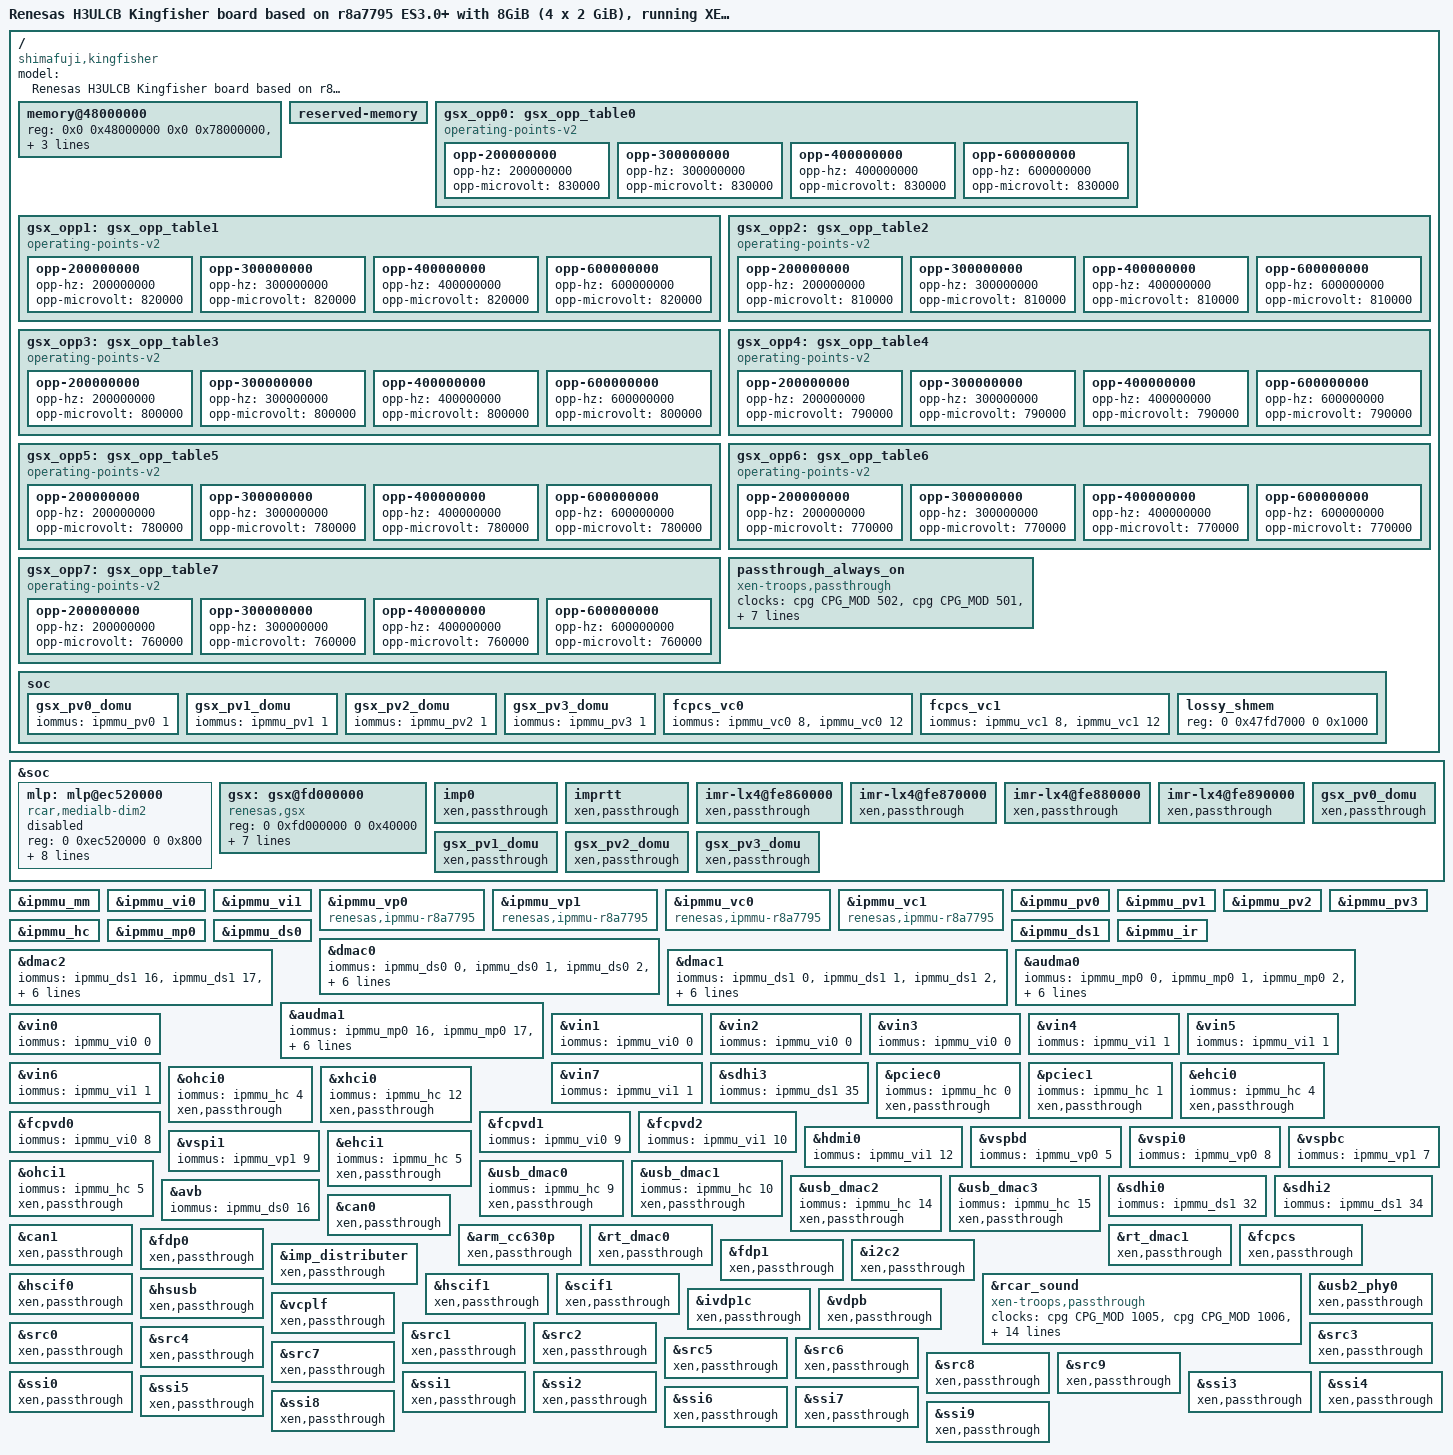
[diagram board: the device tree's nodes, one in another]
/*
 * Device Tree Source for the H3ULCB Kingfisher board
 * running XEN hypervisor
 *
 * Copyright (C) 2016-2018 Renesas Electronics Corp.
 * Copyright (C) 2016 Cogent Embedded, Inc.
 *
 * This file is licensed under the terms of the GNU General Public License
 * version 2.  This program is licensed "as is" without any warranty of any
 * kind, whether express or implied.
 */

#include "r8a77951-ulcb-kf.dts"
#include "xen-chosen.dtsi"

/ {
	model = "Renesas H3ULCB Kingfisher board based on r8a7795 ES3.0+ with 8GiB (4 x 2 GiB), running XEN hypervisor";
	compatible = "shimafuji,kingfisher", "renesas,h3ulcb",
			 "renesas,r8a7795";

	memory@48000000 {
		device_type = "memory";
		/* first 128MB is reserved for secure area. */
		reg = <0x0 0x48000000 0x0 0x78000000>,
			  <0x5 0x00000000 0x0 0x80000000>,
			  <0x6 0x00000000 0x0 0x80000000>,
			  <0x7 0x00000000 0x0 0x80000000>;
	};

	/delete-node/memory@500000000;
	/delete-node/memory@600000000;
	/delete-node/memory@700000000;

	reserved-memory {
		/delete-node/linux,cma@57000000;
		/delete-node/linux,multimedia@70000000;
	};

	/delete-node/mmngr;
	/delete-node/mmngrbuf;

	/*
	 * When creating DT for the guest domain Xen inserts only dummy CPU nodes.
	 * And the number of these inserted CPU nodes is equal to the number of
	 * vCPUs assigned to this domain. All CPU properties which original DT has,
	 * such as OPP, clock, regulator, etc are not passed to the guest’s DT.
	 *
	 * Example of guest vCPU node:
	 *
	 * cpu@0 {
	 *	   device_type = "cpu";
	 *	   compatible = "arm,armv8";
	 *	   enable-method = "psci";
	 *	   reg = <0x0>;
	 * };
	 *
	 * This results in the fact that all features expecting a57_x or a53_x
	 * CPU nodes to be present get broken. This is why we have to explicitly
	 * remove the following.
	 */
	/delete-node/thermal-zones;
	/delete-node/pmu_a57;
	/delete-node/pmu_a53;

	gsx_opp0: gsx_opp_table0 {
		compatible = "operating-points-v2";

		opp-200000000 {
			opp-hz = /bits/ 64 <200000000>;
			opp-microvolt = <830000>;
		};
		opp-300000000 {
			opp-hz = /bits/ 64 <300000000>;
			opp-microvolt = <830000>;
		};
		opp-400000000 {
			opp-hz = /bits/ 64 <400000000>;
			opp-microvolt = <830000>;
		};
		opp-600000000 {
			opp-hz = /bits/ 64 <600000000>;
			opp-microvolt = <830000>;
		};
	};

	gsx_opp1: gsx_opp_table1 {
		compatible = "operating-points-v2";

		opp-200000000 {
			opp-hz = /bits/ 64 <200000000>;
			opp-microvolt = <820000>;
		};
		opp-300000000 {
			opp-hz = /bits/ 64 <300000000>;
			opp-microvolt = <820000>;
		};
		opp-400000000 {
			opp-hz = /bits/ 64 <400000000>;
			opp-microvolt = <820000>;
		};
		opp-600000000 {
			opp-hz = /bits/ 64 <600000000>;
			opp-microvolt = <820000>;
		};
	};

	gsx_opp2: gsx_opp_table2 {
		compatible = "operating-points-v2";

		opp-200000000 {
			opp-hz = /bits/ 64 <200000000>;
			opp-microvolt = <810000>;
		};
		opp-300000000 {
			opp-hz = /bits/ 64 <300000000>;
			opp-microvolt = <810000>;
		};
		opp-400000000 {
			opp-hz = /bits/ 64 <400000000>;
			opp-microvolt = <810000>;
		};
		opp-600000000 {
			opp-hz = /bits/ 64 <600000000>;
			opp-microvolt = <810000>;
		};
	};

	gsx_opp3: gsx_opp_table3 {
		compatible = "operating-points-v2";

		opp-200000000 {
			opp-hz = /bits/ 64 <200000000>;
			opp-microvolt = <800000>;
		};
		opp-300000000 {
			opp-hz = /bits/ 64 <300000000>;
			opp-microvolt = <800000>;
		};
		opp-400000000 {
			opp-hz = /bits/ 64 <400000000>;
			opp-microvolt = <800000>;
		};
		opp-600000000 {
			opp-hz = /bits/ 64 <600000000>;
			opp-microvolt = <800000>;
		};
	};

	gsx_opp4: gsx_opp_table4 {
		compatible = "operating-points-v2";

		opp-200000000 {
			opp-hz = /bits/ 64 <200000000>;
			opp-microvolt = <790000>;
		};
		opp-300000000 {
			opp-hz = /bits/ 64 <300000000>;
			opp-microvolt = <790000>;
		};
		opp-400000000 {
			opp-hz = /bits/ 64 <400000000>;
			opp-microvolt = <790000>;
		};
		opp-600000000 {
			opp-hz = /bits/ 64 <600000000>;
			opp-microvolt = <790000>;
		};
	};

	gsx_opp5: gsx_opp_table5 {
		compatible = "operating-points-v2";

		opp-200000000 {
			opp-hz = /bits/ 64 <200000000>;
			opp-microvolt = <780000>;
		};
		opp-300000000 {
			opp-hz = /bits/ 64 <300000000>;
			opp-microvolt = <780000>;
		};
		opp-400000000 {
			opp-hz = /bits/ 64 <400000000>;
			opp-microvolt = <780000>;
		};
		opp-600000000 {
			opp-hz = /bits/ 64 <600000000>;
			opp-microvolt = <780000>;
		};
	};

	gsx_opp6: gsx_opp_table6 {
		compatible = "operating-points-v2";

		opp-200000000 {
			opp-hz = /bits/ 64 <200000000>;
			opp-microvolt = <770000>;
		};
		opp-300000000 {
			opp-hz = /bits/ 64 <300000000>;
			opp-microvolt = <770000>;
		};
		opp-400000000 {
			opp-hz = /bits/ 64 <400000000>;
			opp-microvolt = <770000>;
		};
		opp-600000000 {
			opp-hz = /bits/ 64 <600000000>;
			opp-microvolt = <770000>;
		};
	};

	gsx_opp7: gsx_opp_table7 {
		compatible = "operating-points-v2";

		opp-200000000 {
			opp-hz = /bits/ 64 <200000000>;
			opp-microvolt = <760000>;
		};
		opp-300000000 {
			opp-hz = /bits/ 64 <300000000>;
			opp-microvolt = <760000>;
		};
		opp-400000000 {
			opp-hz = /bits/ 64 <400000000>;
			opp-microvolt = <760000>;
		};
		opp-600000000 {
			opp-hz = /bits/ 64 <600000000>;
			opp-microvolt = <760000>;
		};
	};

	passthrough_always_on {
		compatible = "xen-troops,passthrough";
		clocks = <&cpg CPG_MOD 502>, /* audma0 */
				 <&cpg CPG_MOD 501>, /* audma1 */
				 <&cpg CPG_MOD 929>, /* audma1 */
				 <&cpg CPG_MOD 703>, <&cpg CPG_MOD 704>, /* hsusb */
				 <&cpg CPG_MOD 330>, /* usb_dmac0 */
				 <&cpg CPG_MOD 331>, /* usb_dmac1 */
				 <&cpg CPG_MOD 328>, /* xhci0 */
				 <&cpg CPG_MOD 702>, /* ohci1 */ /* ehci1 */
				 <&cpg CPG_MOD 218>,  /* dma-controller@e7300000 */
				 <&cpg CPG_MOD 217>,  /* dma-controller@e7310000 */
				 <&cpg CPG_MOD 219>, /* dma-controller@e6700000 */
				 <&cpg CPG_MOD 21>,  /* dma-controller@ffc10000 */
				 <&cpg CPG_MOD 16>,  /* dma-controller@ffc20000 */
				 <&cpg CPG_MOD 326>,  /* dma-controller@e6460000 */
				 <&cpg CPG_MOD 329>;  /* dma-controller@e6470000 */
	};

	/delete-node/sound@0;
};

/* ============================ Nodes, needed for config ===================== */
&soc {
	mlp: mlp@ec520000 {
		compatible = "rcar,medialb-dim2";
		reg = <0 0xec520000 0 0x800>;
		interrupts = <GIC_SPI 384 IRQ_TYPE_LEVEL_HIGH>,
			<GIC_SPI 385 IRQ_TYPE_LEVEL_HIGH>,
			<GIC_SPI 386 IRQ_TYPE_LEVEL_HIGH>,
			<GIC_SPI 387 IRQ_TYPE_LEVEL_HIGH>,
			<GIC_SPI 388 IRQ_TYPE_LEVEL_HIGH>;
		clocks = <&cpg CPG_MOD 802>;
		power-domains = <&sysc R8A7795_PD_ALWAYS_ON>;
		status = "disabled";
	};
	gsx: gsx@fd000000 {
		compatible = "renesas,gsx";
		reg = <0 0xfd000000 0 0x40000>;
		interrupts = <GIC_SPI 119 IRQ_TYPE_LEVEL_HIGH>;
		clocks = <&cpg CPG_MOD 112>;
		operating-points-v2 = <&gsx_opp0>, <&gsx_opp1>,
					  <&gsx_opp2>, <&gsx_opp3>,
					  <&gsx_opp4>, <&gsx_opp5>,
					  <&gsx_opp6>, <&gsx_opp7>;
		power-domains = <&sysc R8A7795_PD_3DG_E>;
		resets = <&cpg 112>;
	};
};

/* ============================ Enabled IPMMUs ===============================*/
&ipmmu_mm {
	status = "okay";
};

&ipmmu_vi0 {
	status = "okay";
};

&ipmmu_vi1 {
	status = "okay";
};

&ipmmu_vp0 {
	compatible = "renesas,ipmmu-r8a7795";
	status = "okay";
};

&ipmmu_vp1 {
	compatible = "renesas,ipmmu-r8a7795";
	status = "okay";
};

&ipmmu_vc0 {
	compatible = "renesas,ipmmu-r8a7795";
	status = "okay";
};

&ipmmu_vc1 {
	compatible = "renesas,ipmmu-r8a7795";
	status = "okay";
};

&ipmmu_pv0 {
	status = "okay";
};

&ipmmu_pv1 {
	status = "okay";
};

&ipmmu_pv2 {
	status = "okay";
};

&ipmmu_pv3 {
	status = "okay";
};

&ipmmu_hc {
	status = "okay";
};

&ipmmu_mp0 {
	status = "okay";
};

&ipmmu_ds0 {
	status = "okay";
};

&ipmmu_ds1 {
	status = "okay";
};

&ipmmu_ir {
	status = "okay";
};

/*=========================== Bus masters linked to IPMMUS ===================*/

&dmac0 {
	iommus = <&ipmmu_ds0 0>, <&ipmmu_ds0 1>,
			 <&ipmmu_ds0 2>, <&ipmmu_ds0 3>,
			 <&ipmmu_ds0 4>, <&ipmmu_ds0 5>,
			 <&ipmmu_ds0 6>, <&ipmmu_ds0 7>,
			 <&ipmmu_ds0 8>, <&ipmmu_ds0 9>,
			 <&ipmmu_ds0 10>, <&ipmmu_ds0 11>,
			 <&ipmmu_ds0 12>, <&ipmmu_ds0 13>,
			 <&ipmmu_ds0 14>, <&ipmmu_ds0 15>;
};

&dmac1 {
	iommus = <&ipmmu_ds1 0>, <&ipmmu_ds1 1>,
			 <&ipmmu_ds1 2>, <&ipmmu_ds1 3>,
			 <&ipmmu_ds1 4>, <&ipmmu_ds1 5>,
			 <&ipmmu_ds1 6>, <&ipmmu_ds1 7>,
			 <&ipmmu_ds1 8>, <&ipmmu_ds1 9>,
			 <&ipmmu_ds1 10>, <&ipmmu_ds1 11>,
			 <&ipmmu_ds1 12>, <&ipmmu_ds1 13>,
			 <&ipmmu_ds1 14>, <&ipmmu_ds1 15>;
};

&dmac2 {
	iommus = <&ipmmu_ds1 16>, <&ipmmu_ds1 17>,
			 <&ipmmu_ds1 18>, <&ipmmu_ds1 19>,
			 <&ipmmu_ds1 20>, <&ipmmu_ds1 21>,
			 <&ipmmu_ds1 22>, <&ipmmu_ds1 23>,
			 <&ipmmu_ds1 24>, <&ipmmu_ds1 25>,
			 <&ipmmu_ds1 26>, <&ipmmu_ds1 27>,
			 <&ipmmu_ds1 28>, <&ipmmu_ds1 29>,
			 <&ipmmu_ds1 30>, <&ipmmu_ds1 31>;
};

&audma0 {
	iommus = <&ipmmu_mp0 0>, <&ipmmu_mp0 1>,
			 <&ipmmu_mp0 2>, <&ipmmu_mp0 3>,
			 <&ipmmu_mp0 4>, <&ipmmu_mp0 5>,
			 <&ipmmu_mp0 6>, <&ipmmu_mp0 7>,
			 <&ipmmu_mp0 8>, <&ipmmu_mp0 9>,
			 <&ipmmu_mp0 10>, <&ipmmu_mp0 11>,
			 <&ipmmu_mp0 12>, <&ipmmu_mp0 13>,
			 <&ipmmu_mp0 14>, <&ipmmu_mp0 15>;
};

&audma1 {
	iommus = <&ipmmu_mp0 16>, <&ipmmu_mp0 17>,
			 <&ipmmu_mp0 18>, <&ipmmu_mp0 19>,
			 <&ipmmu_mp0 20>, <&ipmmu_mp0 21>,
			 <&ipmmu_mp0 22>, <&ipmmu_mp0 23>,
			 <&ipmmu_mp0 24>, <&ipmmu_mp0 25>,
			 <&ipmmu_mp0 26>, <&ipmmu_mp0 27>,
			 <&ipmmu_mp0 28>, <&ipmmu_mp0 29>,
			 <&ipmmu_mp0 30>, <&ipmmu_mp0 31>;
};

&vin0 {
	iommus = <&ipmmu_vi0 0>;
};

&vin1 {
	iommus = <&ipmmu_vi0 0>;
};

&vin2 {
	iommus = <&ipmmu_vi0 0>;
};

&vin3 {
	iommus = <&ipmmu_vi0 0>;
};

&vin4 {
	iommus = <&ipmmu_vi1 1>;
};

&vin5 {
	iommus = <&ipmmu_vi1 1>;
};

&vin6 {
	iommus = <&ipmmu_vi1 1>;
};

&vin7 {
	iommus = <&ipmmu_vi1 1>;
};

&sdhi3 {
	iommus = <&ipmmu_ds1 35>;
};

&pciec0 {
	iommus = <&ipmmu_hc 0>;
};

&pciec1 {
	iommus = <&ipmmu_hc 1>;
};

&ehci0 {
	iommus = <&ipmmu_hc 4>;
};

&ohci0 {
	iommus = <&ipmmu_hc 4>;
};

&xhci0 {
	iommus = <&ipmmu_hc 12>;
};

&mlp {
	iommus = <&ipmmu_mp0 35>;
};

&fcpvd0 {
	iommus = <&ipmmu_vi0 8>;
};

&fcpvd1 {
	iommus = <&ipmmu_vi0 9>;
};

&fcpvd2 {
	iommus = <&ipmmu_vi1 10>;
};

&hdmi0 {
	iommus = <&ipmmu_vi1 12>;
};

&vspbd {
	iommus = <&ipmmu_vp0 5>;
};

&vspi0 {
	iommus = <&ipmmu_vp0 8>;
};

/*
&fcpf0 {
	iommus = <&ipmmu_vp0 0>;
};

&fcpf1 {
	iommus = <&ipmmu_vp1 1>;
};
*/
&vspbc {
	iommus = <&ipmmu_vp1 7>;
};

&vspi1 {
	iommus = <&ipmmu_vp1 9>;
};

/ {
	soc {
		gsx_pv0_domu {
			iommus = <&ipmmu_pv0 1>;
		};

		gsx_pv1_domu {
			iommus = <&ipmmu_pv1 1>;
		};

		gsx_pv2_domu {
			iommus = <&ipmmu_pv2 1>;
		};

		gsx_pv3_domu {
			iommus = <&ipmmu_pv3 1>;
		};

		fcpcs_vc0 {
			iommus = <&ipmmu_vc0 8>,
					 <&ipmmu_vc0 12>;
		};

		fcpcs_vc1 {
			iommus = <&ipmmu_vc1 8>,
					 <&ipmmu_vc1 12>;
		};

		lossy_shmem {
			reg = <0 0x47fd7000 0 0x1000>;
		};
	};
};

&ehci1 {
	iommus = <&ipmmu_hc 5>;
};

&ohci1 {
	iommus = <&ipmmu_hc 5>;
};

&usb_dmac0 {
	iommus = <&ipmmu_hc 9>;
};

&usb_dmac1 {
	iommus = <&ipmmu_hc 10>;
};

&usb_dmac2 {
	iommus = <&ipmmu_hc 14>;
};

&usb_dmac3 {
	iommus = <&ipmmu_hc 15>;
};

&sdhi0 {
	iommus = <&ipmmu_ds1 32>;
};

&sdhi2 {
	iommus = <&ipmmu_ds1 34>;
};

&avb {
	iommus = <&ipmmu_ds0 16>;
};

/* ============================ Xen pass through section =====================*/

&soc {
	imp0  /* imp0*/										{ xen,passthrough; };
	imprtt	/* imprtt*/									{ xen,passthrough; };
	imr-lx4@fe860000  /* imr-lx4@fe860000*/				{ xen,passthrough; };
	imr-lx4@fe870000  /* imr-lx4@fe870000*/				{ xen,passthrough; };
	imr-lx4@fe880000  /* imr-lx4@fe880000*/				{ xen,passthrough; };
	imr-lx4@fe890000  /* imr-lx4@fe890000*/				{ xen,passthrough; };
	gsx_pv0_domu										{ xen,passthrough; };
	gsx_pv1_domu										{ xen,passthrough; };
	gsx_pv2_domu										{ xen,passthrough; };
	gsx_pv3_domu										{ xen,passthrough; };

	//mfis-as											{ xen,passthrough; };

};

// This is autogenerated dts part
&can0 /* can@e6c30000*/								{ xen,passthrough; };
&can1 /* can@e6c38000*/								{ xen,passthrough; };
&arm_cc630p /* crypto@e6601000*/					{ xen,passthrough; };
//&csi20 /* csi2@fea80000*/							{ xen,passthrough; };
//&csi40 /* csi2@feaa0000*/							{ xen,passthrough; };
//&du /* display@feb00000*/							{ xen,passthrough; };
&usb_dmac2 /* dma-controller@e6460000*/				{ xen,passthrough; };
&usb_dmac3 /* dma-controller@e6470000*/				{ xen,passthrough; };
&usb_dmac0 /* dma-controller@e65a0000*/				{ xen,passthrough; };
&usb_dmac1 /* dma-controller@e65b0000*/				{ xen,passthrough; };
&dmac0 /* dma-controller@e6700000*/					{ xen,passthrough; };
&dmac1 /* dma-controller@e7300000*/					{ xen,passthrough; };
&dmac2 /* dma-controller@e7310000*/					{ xen,passthrough; };
&audma0 /* dma-controller@ec700000*/				{ xen,passthrough; };
&audma1 /* dma-controller@ec720000*/				{ xen,passthrough; };
&rt_dmac0 /* dma-controller@ffc10000*/				{ xen,passthrough; };
&rt_dmac1 /* dma-controller@ffc20000*/				{ xen,passthrough; };
//&avb /* ethernet@e6800000*/						{ xen,passthrough; };
//&fcpvd0 /* fcp@fea27000*/							{ xen,passthrough; };
//&fcpvd1 /* fcp@fea2f000*/							{ xen,passthrough; };
//&fcpvd2 /* fcp@fea37000*/							{ xen,passthrough; };
&fcpcs /* vcp4@fe90f000*/							{ xen,passthrough; };
&fdp0 /* fdpm@fe940000*/							{ xen,passthrough; };
&fdp1 /* fdpm@fe944000*/							{ xen,passthrough; };
//&gpio0 /* gpio@e6050000*/							{ xen,passthrough; };
//&gpio1 /* gpio@e6051000*/							{ xen,passthrough; };
//&gpio2 /* gpio@e6052000*/							{ xen,passthrough; };
//&gpio3 /* gpio@e6053000*/							{ xen,passthrough; };
//&gpio4 /* gpio@e6054000*/							{ xen,passthrough; };
//&gpio5 /* gpio@e6055000*/							{ xen,passthrough; };
//&gpio6 /* gpio@e6055400*/							{ xen,passthrough; };
//&gpio7 /* gpio@e6055800*/							{ xen,passthrough; };
//&gsx /* gsx@fd000000*/							{ xen,passthrough; };
//&hdmi0 /* hdmi@fead0000*/							{ xen,passthrough; };
//&i2c_dvfs /* i2c@e60b0000*/						{ xen,passthrough; };
&i2c2 /* i2c@e6510000*/								{ xen,passthrough; };
//&i2c4 /* i2c@e66d8000*/							{ xen,passthrough; };
&imp_distributer /* impdes0*/						{ xen,passthrough; };
//&sdhi0 /* mmc@ee100000*/							{ xen,passthrough; };
//&sdhi2 /* mmc@ee140000*/							{ xen,passthrough; };
//&sdhi3 /* mmc@ee160000*/							{ xen,passthrough; };
//&ipmmu_mm /* mmu@e67b0000*/						{ xen,passthrough; };
&pciec1 /* pcie@ee800000*/							{ xen,passthrough; };
&pciec0 /* pcie@fe000000*/							{ xen,passthrough; };
//&pmic /* pmic@30*/								{ xen,passthrough; };
//&rpc0 /* rpc0@ee200000*/							{ xen,passthrough; };
&hscif0 /* serial@e6540000*/						{ xen,passthrough; };
&hscif1 /* serial@e6550000*/						{ xen,passthrough; };
&scif1 /* serial@e6e68000*/							{ xen,passthrough; };
//&scif2 /* serial@e6e88000							{ xen,passthrough; };
&rcar_sound /* sound@ec500000 */ {
	/* Enable clocks for rcar_sound from here because it appears
	 * that rcar_sound device inits prior to xen-passthrough driver.
	 * Setting those clocks in passthrough_always_on produces kernel Oops
	 * during rcar_sound initialization.
	*/
	compatible = "xen-troops,passthrough";
	clocks = <&cpg CPG_MOD 1005>, /* rcar_sound */
				 <&cpg CPG_MOD 1006>, <&cpg CPG_MOD 1007>,
				 <&cpg CPG_MOD 1008>, <&cpg CPG_MOD 1009>,
				 <&cpg CPG_MOD 1010>, <&cpg CPG_MOD 1011>,
				 <&cpg CPG_MOD 1012>, <&cpg CPG_MOD 1013>,
				 <&cpg CPG_MOD 1014>, <&cpg CPG_MOD 1015>,
				 <&cpg CPG_MOD 1022>, <&cpg CPG_MOD 1023>,
				 <&cpg CPG_MOD 1024>, <&cpg CPG_MOD 1025>,
				 <&cpg CPG_MOD 1026>, <&cpg CPG_MOD 1027>,
				 <&cpg CPG_MOD 1028>, <&cpg CPG_MOD 1029>,
				 <&cpg CPG_MOD 1030>, <&cpg CPG_MOD 1031>,
				 <&cpg CPG_MOD 1020>, <&cpg CPG_MOD 1021>,
				 <&cpg CPG_MOD 1020>, <&cpg CPG_MOD 1021>,
				 <&cpg CPG_MOD 1019>, <&cpg CPG_MOD 1018>,
				 <&cpg CPG_CORE CPG_AUDIO_CLK_I>;

};
//&tsc /* thermal@e6198000*/						{ xen,passthrough; };
&usb2_phy0 /* usb-phy@ee080200*/					{ xen,passthrough; };
&hsusb /* usb@e6590000*/							{ xen,passthrough; };
&xhci0 /* usb@ee000000*/							{ xen,passthrough; };
&ohci0 /* usb@ee080000*/							{ xen,passthrough; };
&ehci0 /* usb@ee080100*/							{ xen,passthrough; };
&ohci1 /* usb@ee0a0000*/							{ xen,passthrough; };
&ehci1 /* usb@ee0a0100*/							{ xen,passthrough; };
&ivdp1c /* vcp4@fe8d0000*/							{ xen,passthrough; };
&vdpb /* vcp4@fe900000*/							{ xen,passthrough; };
&vcplf /* vcp4@fe910000*/							{ xen,passthrough; };
//&vin0 /* video@e6ef0000*/							{ xen,passthrough; };
//&vin1 /* video@e6ef1000*/							{ xen,passthrough; };
//&vin2 /* video@e6ef2000*/							{ xen,passthrough; };
//&vin3 /* video@e6ef3000*/							{ xen,passthrough; };
//&vin4 /* video@e6ef4000*/							{ xen,passthrough; };
//&vin5 /* video@e6ef5000*/							{ xen,passthrough; };
//&vspd0 /* vsp@fea20000*/							{ xen,passthrough; };
//&vspd1 /* vsp@fea28000*/							{ xen,passthrough; };
//&vspd2 /* vsp@fea30000*/							{ xen,passthrough; };
//&vspbc /* vspm@fe920000*/							{ xen,passthrough; };
//&vspbd /* vspm@fe960000*/							{ xen,passthrough; };
//&vspi0 /* vspm@fe9a0000*/							{ xen,passthrough; };
//&vspi1 /* vspm@fe9b0000*/							{ xen,passthrough; };

&src0									{ xen,passthrough; };
&src1									{ xen,passthrough; };
&src2									{ xen,passthrough; };
&src3									{ xen,passthrough; };
&src4									{ xen,passthrough; };
&src5									{ xen,passthrough; };
&src6									{ xen,passthrough; };
&src7									{ xen,passthrough; };
&src8									{ xen,passthrough; };
&src9									{ xen,passthrough; };
&ssi0									{ xen,passthrough; };
&ssi1									{ xen,passthrough; };
&ssi2									{ xen,passthrough; };
&ssi3									{ xen,passthrough; };
&ssi4									{ xen,passthrough; };
&ssi5									{ xen,passthrough; };
&ssi6									{ xen,passthrough; };
&ssi7									{ xen,passthrough; };
&ssi8									{ xen,passthrough; };
&ssi9									{ xen,passthrough; };

// End of autogenerated dts part
